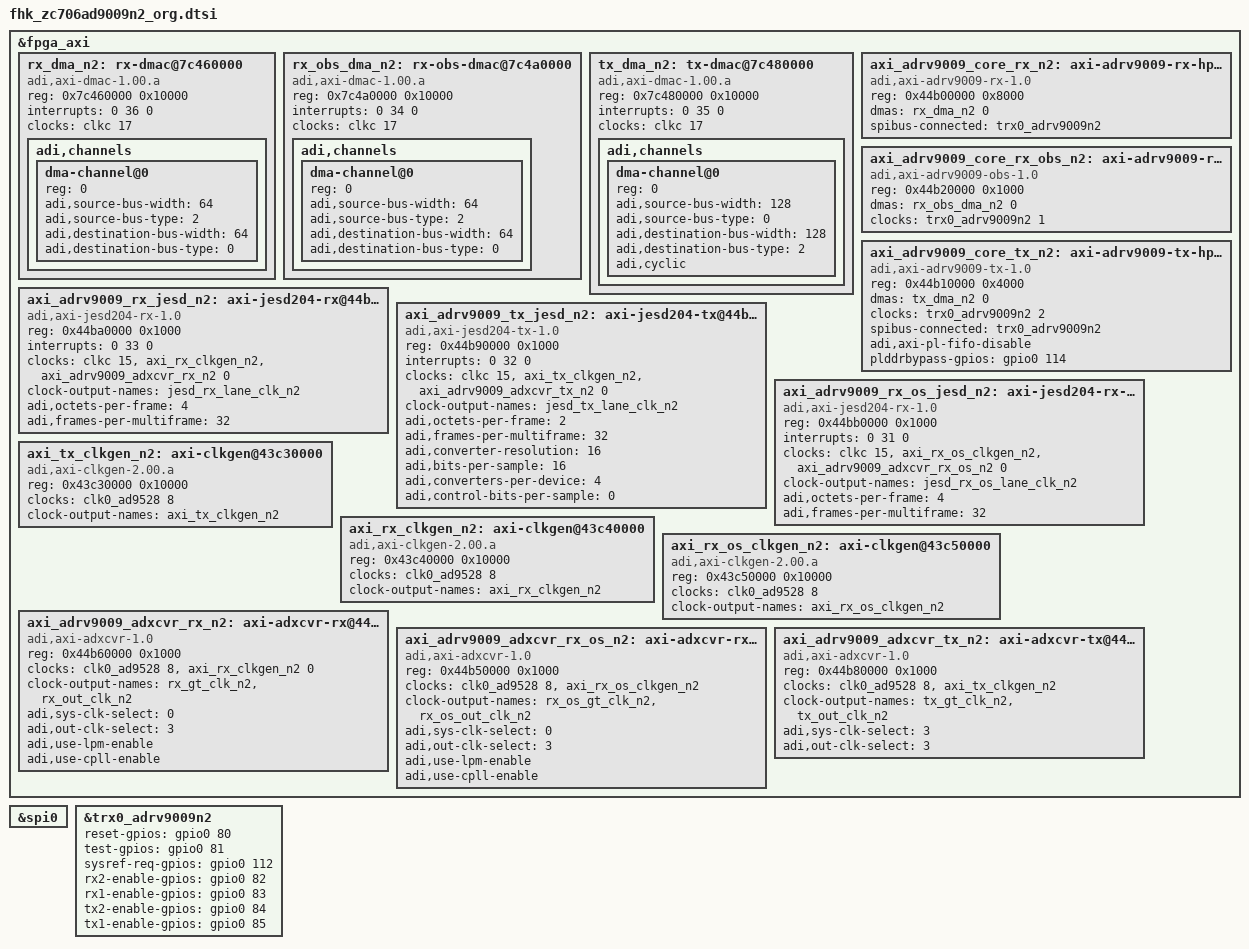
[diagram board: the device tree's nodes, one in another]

&fpga_axi {
	rx_dma_n2: rx-dmac@7c460000 {
		compatible = "adi,axi-dmac-1.00.a";
		reg = <0x7c460000 0x10000>;
		#dma-cells = <1>;
		interrupts = <0 36 0>; // UG858, Table 7-4: IRQF2P[7] -> IRQ[68-32]
		clocks = <&clkc 17>;

		adi,channels {
			#size-cells = <0>;
			#address-cells = <1>;

			dma-channel@0 {
				reg = <0>;
				adi,source-bus-width = <64>;
				adi,source-bus-type = <2>;
				adi,destination-bus-width = <64>;
				adi,destination-bus-type = <0>;
			};
		};
	};

	rx_obs_dma_n2: rx-obs-dmac@7c4a0000  {
		compatible = "adi,axi-dmac-1.00.a";
		reg = <0x7c4a0000  0x10000>;
		#dma-cells = <1>;
		interrupts = <0 34 0>; // UG858, Table 7-4: IRQF2P[5] -> IRQ[66-32]
		clocks = <&clkc 17>;

		adi,channels {
			#size-cells = <0>;
			#address-cells = <1>;

			dma-channel@0 {
				reg = <0>;
				adi,source-bus-width = <64>;
				adi,source-bus-type = <2>;
				adi,destination-bus-width = <64>;
				adi,destination-bus-type = <0>;
			};
		};
	};

	tx_dma_n2: tx-dmac@7c480000 {
		compatible = "adi,axi-dmac-1.00.a";
		reg = <0x7c480000 0x10000>;
		#dma-cells = <1>;
		interrupts = <0 35 0>; // UG858, Table 7-4: IRQF2P[6] -> IRQ[67-32]
		clocks = <&clkc 17>;

		adi,channels {
			#size-cells = <0>;
			#address-cells = <1>;

			dma-channel@0 {
				reg = <0>;
				adi,source-bus-width = <128>;
				adi,source-bus-type = <0>;
				adi,destination-bus-width = <128>;
				adi,destination-bus-type = <2>;
				adi,cyclic;
			};
		};
	};

	axi_adrv9009_core_rx_n2: axi-adrv9009-rx-hpc@44b00000 {
		compatible = "adi,axi-adrv9009-rx-1.0";
		reg = <0x44b00000 0x8000>;
		dmas = <&rx_dma_n2 0>;
		dma-names = "rx"; // the name is aligned with the driver
		spibus-connected = <&trx0_adrv9009n2>;
	};

	axi_adrv9009_core_rx_obs_n2: axi-adrv9009-rx-obs-hpc@44b20000 {
		compatible = "adi,axi-adrv9009-obs-1.0";
		reg = <0x44b20000 0x1000>;
		dmas = <&rx_obs_dma_n2 0>;
		dma-names = "rx"; // the name is aligned with the driver
		clocks = <&trx0_adrv9009n2 1>;
		clock-names = "sampl_clk"; // the name is aligned with the driver
	};

	axi_adrv9009_core_tx_n2: axi-adrv9009-tx-hpc@44b10000 {
		compatible = "adi,axi-adrv9009-tx-1.0";
		reg = <0x44b10000 0x4000>;
		dmas = <&tx_dma_n2 0>;
		dma-names = "tx"; // the name is aligned with the driver
		clocks = <&trx0_adrv9009n2 2>;
		clock-names = "sampl_clk"; // the name is aligned with the driver
		spibus-connected = <&trx0_adrv9009n2>;
		adi,axi-pl-fifo-disable;//adi,axi-pl-fifo-enable; see "plddrbypass-gpios"
	};

	axi_adrv9009_rx_jesd_n2: axi-jesd204-rx@44ba0000 {
		compatible = "adi,axi-jesd204-rx-1.0";
		reg = <0x44ba0000 0x1000>;

		interrupts = <0 33 0>; // UG858, Table 7-4: IRQF2P[4] -> IRQ[65-32]

		clocks = <&clkc 15>, <&axi_rx_clkgen_n2>, <&axi_adrv9009_adxcvr_rx_n2 0>;
		clock-names = "s_axi_aclk", "device_clk", "lane_clk"; // the name is aligned with the driver

		#clock-cells = <0>;
		clock-output-names = "jesd_rx_lane_clk_n2";

		adi,octets-per-frame = <4>;
		adi,frames-per-multiframe = <32>;
	};

	axi_adrv9009_tx_jesd_n2: axi-jesd204-tx@44b90000 {
		compatible = "adi,axi-jesd204-tx-1.0";
		reg = <0x44b90000 0x1000>;

		interrupts = <0 32 0>; // UG858, Table 7-4: IRQF2P[3] -> IRQ[64-32]

		clocks = <&clkc 15>, <&axi_tx_clkgen_n2>, <&axi_adrv9009_adxcvr_tx_n2 0>;
		clock-names = "s_axi_aclk", "device_clk", "lane_clk"; // the name is aligned with the driver

		#clock-cells = <0>;
		clock-output-names = "jesd_tx_lane_clk_n2";

		adi,octets-per-frame = <2>;
		adi,frames-per-multiframe = <32>;
		adi,converter-resolution = <16>;
		adi,bits-per-sample = <16>;
		adi,converters-per-device = <4>;
		adi,control-bits-per-sample = <0>;
	};

  	axi_adrv9009_rx_os_jesd_n2: axi-jesd204-rx-os@44bb0000 {
		compatible = "adi,axi-jesd204-rx-1.0";
		reg = <0x44bb0000 0x1000>;

		interrupts = <0 31 0>; // UG858, Table 7-4: IRQF2P[2] -> IRQ[63-32]

		clocks = <&clkc 15>, <&axi_rx_os_clkgen_n2>, <&axi_adrv9009_adxcvr_rx_os_n2 0>;
		clock-names = "s_axi_aclk", "device_clk", "lane_clk"; // the name is aligned with the driver

		#clock-cells = <0>;
		clock-output-names = "jesd_rx_os_lane_clk_n2";

		adi,octets-per-frame = <4>;
		adi,frames-per-multiframe = <32>;
	};

	axi_tx_clkgen_n2: axi-clkgen@43c30000  {
		compatible = "adi,axi-clkgen-2.00.a";
		reg = <0x43c30000 0x10000>;
		#clock-cells = <0>;
		clocks = <&clk0_ad9528 8>;
		clock-output-names = "axi_tx_clkgen_n2";
	};

	axi_rx_clkgen_n2: axi-clkgen@43c40000  {
		compatible = "adi,axi-clkgen-2.00.a";
		reg = <0x43c40000 0x10000>;
		#clock-cells = <0>;
		clocks = <&clk0_ad9528 8>;
		clock-output-names = "axi_rx_clkgen_n2";
	};

	axi_rx_os_clkgen_n2: axi-clkgen@43c50000  {
		compatible = "adi,axi-clkgen-2.00.a";
		reg = <0x43c50000 0x10000>;
		#clock-cells = <0>;
		clocks = <&clk0_ad9528 8>;
		clock-output-names = "axi_rx_os_clkgen_n2";
	};

	axi_adrv9009_adxcvr_rx_n2: axi-adxcvr-rx@44b60000 {
		#address-cells = <1>;
		#size-cells = <0>;
		compatible = "adi,axi-adxcvr-1.0";
		reg = <0x44b60000 0x1000>;

		clocks = <&clk0_ad9528 8>, <&axi_rx_clkgen_n2 0>;
		clock-names = "conv", "div40"; // the name is aligned with the driver

		#clock-cells = <1>;
		clock-output-names = "rx_gt_clk_n2", "rx_out_clk_n2";

		adi,sys-clk-select = <0>;
		adi,out-clk-select = <3>;
		adi,use-lpm-enable;
		adi,use-cpll-enable;
	};

	axi_adrv9009_adxcvr_rx_os_n2: axi-adxcvr-rx-os@44b50000 {
		#address-cells = <1>;
		#size-cells = <0>;
		compatible = "adi,axi-adxcvr-1.0";
		reg = <0x44b50000 0x1000>;

		clocks = <&clk0_ad9528 8>, <&axi_rx_os_clkgen_n2>;
		clock-names = "conv", "div40"; // the name is aligned with the driver

		#clock-cells = <1>;
		clock-output-names = "rx_os_gt_clk_n2", "rx_os_out_clk_n2";

		adi,sys-clk-select = <0>;
		adi,out-clk-select = <3>;
		adi,use-lpm-enable;
		adi,use-cpll-enable;
	};

	axi_adrv9009_adxcvr_tx_n2: axi-adxcvr-tx@44b80000 {
		#address-cells = <1>;
		#size-cells = <0>;
		compatible = "adi,axi-adxcvr-1.0";
		reg = <0x44b80000 0x1000>;

		clocks = <&clk0_ad9528 8>, <&axi_tx_clkgen_n2>;
		clock-names = "conv", "div40"; // the name is aligned with the driver

		#clock-cells = <1>;
		clock-output-names = "tx_gt_clk_n2", "tx_out_clk_n2";

		adi,sys-clk-select = <3>;
		adi,out-clk-select = <3>;
	};
};

&spi0 {
	status = "okay";
};

#define fmc_spi spi0

#include "fhk_adrv9009n2_org.dtsi"

// adrv9009_dac_fifo_bypass_s 60
// ad9528_reset_b,       // 59
// ad9528_sysref_req,    // 58
// adrv9009_tx1_enable,    // 31
// adrv9009_tx2_enable,    // 30
// adrv9009_rx1_enable,    // 29
// adrv9009_rx2_enable,    // 28
// adrv9009_test,          // 27
// adrv9009_reset_b,       // 26
// adrv9009_gpint,         // 25
// adrv9009_gpio_00,       // 24
// adrv9009_gpio_01,       // 23
// adrv9009_gpio_02,       // 22
// adrv9009_gpio_03,       // 21
// adrv9009_gpio_04,       // 20
// adrv9009_gpio_05,       // 19
// adrv9009_gpio_06,       // 18
// adrv9009_gpio_07,       // 17
// adrv9009_gpio_15,       // 16
// adrv9009_gpio_08,       // 15
// adrv9009_gpio_09,       // 14
// adrv9009_gpio_10,       // 13
// adrv9009_gpio_11,       // 12
// adrv9009_gpio_12,       // 11
// adrv9009_gpio_14,       // 10
// adrv9009_gpio_13,       //  9
// adrv9009_gpio_17,       //  8
// adrv9009_gpio_16,       //  7
// adrv9009_gpio_18}));    //  6 + 54

&trx0_adrv9009n2 {
	reset-gpios = <&gpio0 80 0>;
	test-gpios = <&gpio0 81 0>;
	sysref-req-gpios = <&gpio0 112 0>;
	rx2-enable-gpios = <&gpio0 82 0>;
	rx1-enable-gpios = <&gpio0 83 0>;
	tx2-enable-gpios = <&gpio0 84 0>;
	tx1-enable-gpios = <&gpio0 85 0>;
};


&axi_adrv9009_core_tx_n2 {
	plddrbypass-gpios = <&gpio0 114 0>;
};
